# ddr32ss_EMIF_CTLCFG_0F308000h register map
Vendor: Texas Instruments
Registers are 32-bit, read-write, reset 0x0 unless marked. A register's access mark holds for its fields unless they carry their own. Offsets are as the file gives them; [hi:lo] are bit positions; lines under a group give offsets from that group; {n}, {i} and the like mark numbered series.

## emif_ctlcfg (part 13 of 13)
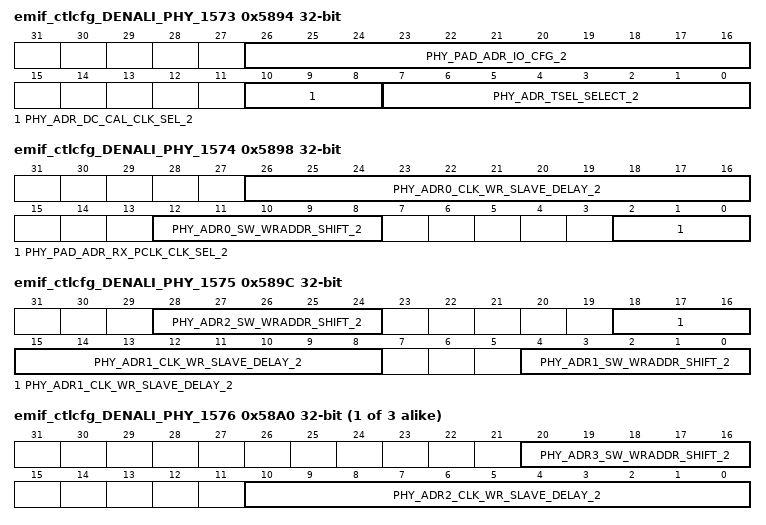
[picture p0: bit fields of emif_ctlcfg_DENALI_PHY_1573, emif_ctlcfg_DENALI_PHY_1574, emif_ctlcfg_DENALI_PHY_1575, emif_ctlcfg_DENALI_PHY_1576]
0x5894 emif_ctlcfg_DENALI_PHY_1573
  [26:16] PHY_PAD_ADR_IO_CFG_2 — Controls I/O pads for address pad for address slice 2. Bits [10:5] = Park value, bits [4] park override, bits [2:0] clk divider. Reset Source: ctl_amod_g_rst_n
  [10:8] PHY_ADR_DC_CAL_CLK_SEL_2 — DCC CAL clock for address slice 2. Reset Source: ctl_amod_g_rst_n
  [7:0] PHY_ADR_TSEL_SELECT_2 — Tsel select values for address slice 2. Reset Source: ctl_amod_g_rst_n
0x5898 emif_ctlcfg_DENALI_PHY_1574
  [26:16] PHY_ADR0_CLK_WR_SLAVE_DELAY_2 — CA bit 0 target delay setting for address slice 2. Reset Source: ctl_amod_g_rst_n
  [12:8] PHY_ADR0_SW_WRADDR_SHIFT_2 — Manual override of CA bit 0 of automatic half_cycle_shift/cycle_shift for address slice 2. Bit [0] enables override of half_cycle_shift. Bit [1] is the half_cycle_shift value. Bit [2] enables override of cycle shift. Bits [4:3] is the cycle_shift value. For bits [4:3], clear to 0x0 for no offset, program to 0x1 for -1 cycle, program to 0x2 for +1 cycle, or program to 0x3 for -2 cycles. Reset Source: ctl_amod_g_rst_n
  [2:0] PHY_PAD_ADR_RX_PCLK_CLK_SEL_2 — Reserved for address slice 2. Reset Source: ctl_amod_g_rst_n
0x589C emif_ctlcfg_DENALI_PHY_1575
  [28:24] PHY_ADR2_SW_WRADDR_SHIFT_2 — Manual override of CA bit 2 of automatic half_cycle_shift/cycle_shift for address slice 2. Bit [0] enables override of half_cycle_shift. Bit [1] is the half_cycle_shift value. Bit [2] enables override of cycle shift. Bits [4:3] is the cycle_shift value. For bits [4:3], clear to 0x0 for no offset, program to 0x1 for -1 cycle, program to 0x2 for +1 cycle, or program to 0x3 for -2 cycles. Reset Source: ctl_amod_g_rst_n
  [18:8] PHY_ADR1_CLK_WR_SLAVE_DELAY_2 — CA bit 1 target delay setting for address slice 2. Reset Source: ctl_amod_g_rst_n
  [4:0] PHY_ADR1_SW_WRADDR_SHIFT_2 — Manual override of CA bit 1 of automatic half_cycle_shift/cycle_shift for address slice 2. Bit [0] enables override of half_cycle_shift. Bit [1] is the half_cycle_shift value. Bit [2] enables override of cycle shift. Bits [4:3] is the cycle_shift value. For bits [4:3], clear to 0x0 for no offset, program to 0x1 for -1 cycle, program to 0x2 for +1 cycle, or program to 0x3 for -2 cycles. Reset Source: ctl_amod_g_rst_n
{0x4000+4i} emif_ctlcfg_DENALI_PHY_{i} (i=1576..1578)
  [20:16] PHY_ADR{i-1573}_SW_WRADDR_SHIFT_2 — Manual override of CA bit {i-1573} of automatic half_cycle_shift/cycle_shift for address slice 2. Bit [0] enables override of half_cycle_shift. Bit [1] is the half_cycle_shift value. Bit [2] enables override of cycle shift. Bits [4:3] is the cycle_shift value. For bits [4:3], clear to 0x0 for no offset, program to 0x1 for -1 cycle, program to 0x2 for +1 cycle, or program to 0x3 for -2 cycles. Reset Source: ctl_amod_g_rst_n
  [10:0] PHY_ADR{i-1574}_CLK_WR_SLAVE_DELAY_2 — CA bit {i-1574} target delay setting for address slice 2. Reset Source: ctl_amod_g_rst_n
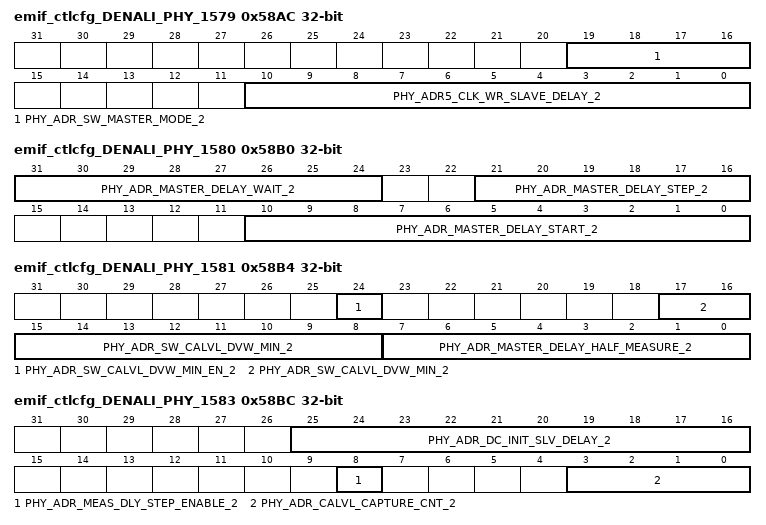
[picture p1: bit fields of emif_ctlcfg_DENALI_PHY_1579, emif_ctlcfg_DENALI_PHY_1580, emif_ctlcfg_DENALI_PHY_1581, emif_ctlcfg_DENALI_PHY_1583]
0x58AC emif_ctlcfg_DENALI_PHY_1579
  [19:16] PHY_ADR_SW_MASTER_MODE_2 — Master delay line override settings for address slice 2. Bit [0] enables software half clock mode. Bit [1] is the software half clock mode value. Bit [2] enables software bypass mode. Bit [3] is the software bypass mode value. Reset Source: ctl_amod_g_rst_n
  [10:0] PHY_ADR5_CLK_WR_SLAVE_DELAY_2 — CA bit 5 target delay setting for address slice 2. Reset Source: ctl_amod_g_rst_n
0x58B0 emif_ctlcfg_DENALI_PHY_1580
  [31:24] PHY_ADR_MASTER_DELAY_WAIT_2 — Wait cycles for master delay line locking algorithm for address slice 2. Bits [3:0] is the cycle wait count after a calibration clock setting change. Bits [7:4] is the cycle wait count after a master delay setting change. Reset Source: ctl_amod_g_rst_n
  [21:16] PHY_ADR_MASTER_DELAY_STEP_2 — Incremental step size for master delay line locking algorithm for address slice 2. Reset Source: ctl_amod_g_rst_n
  [10:0] PHY_ADR_MASTER_DELAY_START_2 — Start value for master delay line locking algorithm for address slice 2. Reset Source: ctl_amod_g_rst_n
0x58B4 emif_ctlcfg_DENALI_PHY_1581
  [24] PHY_ADR_SW_CALVL_DVW_MIN_EN_2 — Enables the software override data valid window size during CA training for address slice 2. Reset Source: ctl_amod_g_rst_n
  [17:8] PHY_ADR_SW_CALVL_DVW_MIN_2 — Sets the software override data valid window size during CA training for address slice 2. Reset Source: ctl_amod_g_rst_n
  [7:0] PHY_ADR_MASTER_DELAY_HALF_MEASURE_2 — Defines the number of delay line elements to be considered in determing whether to lock to a half clock cycle for the master in address slice 2 Reset Source: ctl_amod_g_rst_n
0x58B8 emif_ctlcfg_DENALI_PHY_1582
  [3:0] PHY_ADR_CALVL_DLY_STEP_2 — Sets the delay step size plus 1 during CA training for address slice 2. Reset Source: ctl_amod_g_rst_n
0x58BC emif_ctlcfg_DENALI_PHY_1583
  [25:16] PHY_ADR_DC_INIT_SLV_DELAY_2 — DCC initialization value of write ADDR target delay for address slice 2. Reset Source: ctl_amod_g_rst_n
  [8] PHY_ADR_MEAS_DLY_STEP_ENABLE_2 — Enables delay parameter setting using phy_adr_meas_dly_step_value for address slice 2. Reset Source: ctl_amod_g_rst_n
  [3:0] PHY_ADR_CALVL_CAPTURE_CNT_2 — Number of samples to take at each ADDR target delay setting during CA training for address slice 2. Reset Source: ctl_amod_g_rst_n
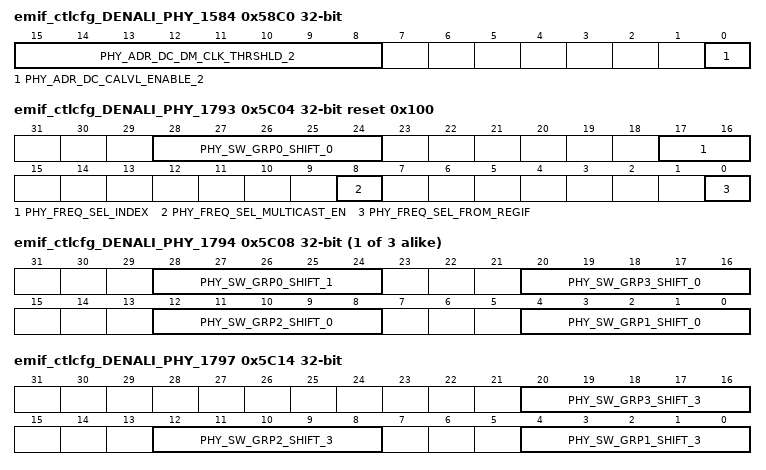
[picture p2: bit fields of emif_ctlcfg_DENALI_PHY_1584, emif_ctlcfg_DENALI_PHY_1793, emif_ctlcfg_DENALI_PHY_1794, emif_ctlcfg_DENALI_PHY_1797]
0x58C0 emif_ctlcfg_DENALI_PHY_1584
  [15:8] PHY_ADR_DC_DM_CLK_THRSHLD_2 — DCC clock measurement cell threshold offset for address slice 2. Reset Source: ctl_amod_g_rst_n
  [0] PHY_ADR_DC_CALVL_ENABLE_2 — DCC enable duty cycle adjust during CA leveling for address slice 2. Reset Source: ctl_amod_g_rst_n
0x5C00 emif_ctlcfg_DENALI_PHY_1792
  [1:0] PHY_FREQ_SEL — Specifies which copy of the frequency-dependent timing parameters will be used by the PHY. Reset Source: ctl_amod_g_rst_n
0x5C04 emif_ctlcfg_DENALI_PHY_1793 reset 0x100
  [28:24] PHY_SW_GRP0_SHIFT_0 — Address slice target delay setting for address slice 4. Reset Source: ctl_amod_g_rst_n
  [17:16] PHY_FREQ_SEL_INDEX — Selects which frequency set to update when PHY_FREQ_SEL_MULTICAST_EN is not set. Reset Source: ctl_amod_g_rst_n
  [8] PHY_FREQ_SEL_MULTICAST_EN — When set, a register write will update parameters for all frequency sets simultaneously. Set to 1 to enable. Reset Source: ctl_amod_g_rst_n
  [0] PHY_FREQ_SEL_FROM_REGIF — Indicates which source is used to select the frequency copy. When set to 1, the frequency select source is given by parameter PHY_FREQ_SEL from register I/F. When cleared to 0, the frequency select source is the PHY input signal dfi_frequency Reset Source: ctl_amod_g_rst_n
{0x4000+4i} emif_ctlcfg_DENALI_PHY_{i} (i=1794..1796)
  [28:24] PHY_SW_GRP0_SHIFT_{i-1793} — Address slice target delay setting for address slice 4. Reset Source: ctl_amod_g_rst_n
  [20:16] PHY_SW_GRP3_SHIFT_{i-1794} — Address slice target delay setting for address slice 4. Reset Source: ctl_amod_g_rst_n
  [12:8] PHY_SW_GRP2_SHIFT_{i-1794} — Address slice target delay setting for address slice 4. Reset Source: ctl_amod_g_rst_n
  [4:0] PHY_SW_GRP1_SHIFT_{i-1794} — Address slice target delay setting for address slice 4. Reset Source: ctl_amod_g_rst_n
0x5C14 emif_ctlcfg_DENALI_PHY_1797
  [20:16] PHY_SW_GRP3_SHIFT_3 — Address slice target delay setting for address slice 4. Reset Source: ctl_amod_g_rst_n
  [12:8] PHY_SW_GRP2_SHIFT_3 — Address slice target delay setting for address slice 4. Reset Source: ctl_amod_g_rst_n
  [4:0] PHY_SW_GRP1_SHIFT_3 — Address slice target delay setting for address slice 4. Reset Source: ctl_amod_g_rst_n
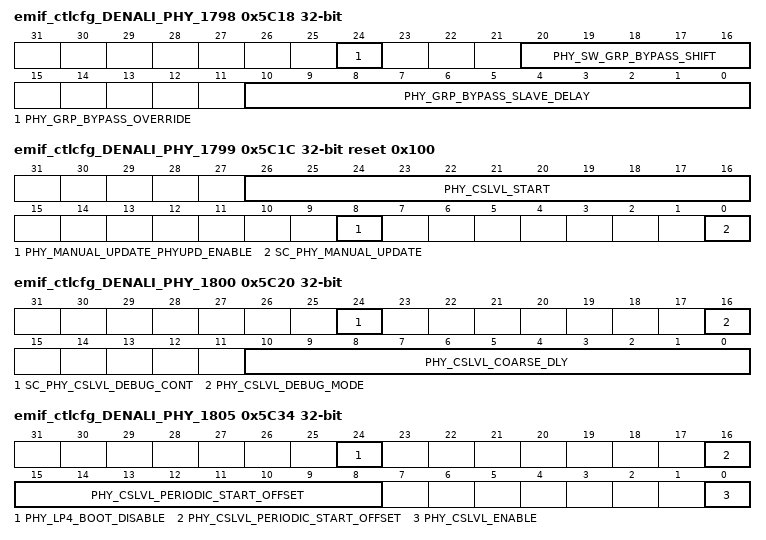
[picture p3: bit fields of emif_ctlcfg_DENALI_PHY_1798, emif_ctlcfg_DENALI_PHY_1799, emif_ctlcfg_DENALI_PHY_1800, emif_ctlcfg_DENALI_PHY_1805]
0x5C18 emif_ctlcfg_DENALI_PHY_1798
  [24] PHY_GRP_BYPASS_OVERRIDE — Address/control group slice bypass mode override setting. Reset Source: ctl_amod_g_rst_n
  [20:16] PHY_SW_GRP_BYPASS_SHIFT — Address/control group slice bypass mode shift settings. Reset Source: ctl_amod_g_rst_n
  [10:0] PHY_GRP_BYPASS_SLAVE_DELAY — Address/control group slice bypass mode target delay setting. Reset Source: ctl_amod_g_rst_n
0x5C1C emif_ctlcfg_DENALI_PHY_1799 access per field reset 0x100
  [26:16] PHY_CSLVL_START rw — Defines the CS training DDL start value. Reset Source: ctl_amod_g_rst_n
  [8] PHY_MANUAL_UPDATE_PHYUPD_ENABLE rw — Manual update selection of all target delay line settings. Set 1 to assert phyupd_req and wait phyupd_ack to update delay line, set 0 to update delay line directly. Reset Source: ctl_amod_g_rst_n
  [0] SC_PHY_MANUAL_UPDATE wo — Manual update of all target delay line settings. Set to 1 to trigger. WRITE-ONLY Reset Source: ctl_amod_g_rst_n
0x5C20 emif_ctlcfg_DENALI_PHY_1800 access per field
  [24] SC_PHY_CSLVL_DEBUG_CONT wo — Allows the CS training state machine to advance [when in debug mode]. Set to 1 to trigger. WRITE-ONLY Reset Source: ctl_amod_g_rst_n
  [16] PHY_CSLVL_DEBUG_MODE rw — Enables CS training debug mode. Set to 1 to enable. Reset Source: ctl_amod_g_rst_n
  [10:0] PHY_CSLVL_COARSE_DLY rw — Defines the CS training DDL coarse cycle delay value. Reset Source: ctl_amod_g_rst_n
0x5C24 emif_ctlcfg_DENALI_PHY_1801 wo
  [0] SC_PHY_CSLVL_ERROR_CLR — Clears the CS training state machine error status. Set to 1 to trigger. WRITE-ONLY Reset Source: ctl_amod_g_rst_n
0x5C28 emif_ctlcfg_DENALI_PHY_1802 ro reset 0x6800000
  [31:0] PHY_CSLVL_OBS0 — Observation register for CS training delay values. READ-ONLY Reset Source: ctl_amod_g_rst_n
0x5C2C emif_ctlcfg_DENALI_PHY_1803 ro
  [31:0] PHY_CSLVL_OBS1 — Observation register for CS training algorithm status. READ-ONLY Reset Source: ctl_amod_g_rst_n
0x5C30 emif_ctlcfg_DENALI_PHY_1804 ro
  [31:0] PHY_CSLVL_OBS2 — Observation register for periodic CS training delay values. READ-ONLY Reset Source: ctl_amod_g_rst_n
0x5C34 emif_ctlcfg_DENALI_PHY_1805
  [24] PHY_LP4_BOOT_DISABLE — Controls the handling of the DFI frequency. When set to 1, DFI frequency 0 is considered the first operational frequency. When cleared to 0, DFI frequency 0 is the boot frequency and other DFI frequency values are operational frequencies. Must be cleared to 0 for LPDDR3 devices operating in an LPDDR4 capable configuration. Reset Source: ctl_amod_g_rst_n
  [16:8] PHY_CSLVL_PERIODIC_START_OFFSET — Defines the relative offset from previous LE and TE to start periodic CSLVL with. Reset Source: ctl_amod_g_rst_n
  [0] PHY_CSLVL_ENABLE — CS training enable. Set to 1 to enable CS training during CA training. Reset Source: ctl_amod_g_rst_n
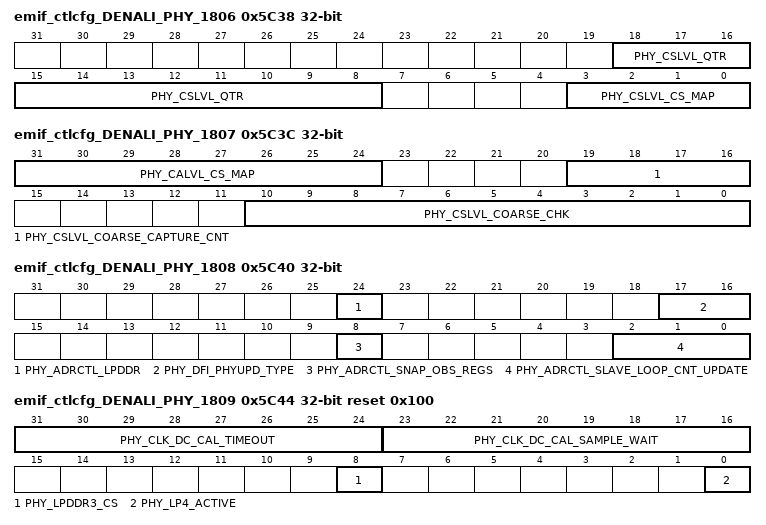
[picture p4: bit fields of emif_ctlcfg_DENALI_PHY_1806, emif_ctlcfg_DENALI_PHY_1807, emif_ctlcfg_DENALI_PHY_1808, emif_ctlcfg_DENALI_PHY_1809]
0x5C38 emif_ctlcfg_DENALI_PHY_1806
  [18:8] PHY_CSLVL_QTR — Defines the CS training DDL 1/4 cycle delay value. Reset Source: ctl_amod_g_rst_n
  [3:0] PHY_CSLVL_CS_MAP — CS training map. Set each CS bit to 1 to allow that CS to participate in CS training results. NOT CURRENTLY USED. Reset Source: ctl_amod_g_rst_n
0x5C3C emif_ctlcfg_DENALI_PHY_1807
  [31:24] PHY_CALVL_CS_MAP — Defines the slice numbers associated with each CS during CA training. Reset Source: ctl_amod_g_rst_n
  [19:16] PHY_CSLVL_COARSE_CAPTURE_CNT — Defines the number of samples to take at each GRP target delay setting during CS training coarse CA training. Reset Source: ctl_amod_g_rst_n
  [10:0] PHY_CSLVL_COARSE_CHK — Defines the CS training coarse CA training DDL 1/16th cycle delay value. Reset Source: ctl_amod_g_rst_n
0x5C40 emif_ctlcfg_DENALI_PHY_1808 access per field
  [24] PHY_ADRCTL_LPDDR rw — Adds a cycle of delay for the address/control slices to match the address slice. Reset Source: ctl_amod_g_rst_n
  [17:16] PHY_DFI_PHYUPD_TYPE rw — Defines the value of the dfi_phyupd_type output signal to MC. Reset Source: ctl_amod_g_rst_n
  [8] PHY_ADRCTL_SNAP_OBS_REGS wo — Initiates a snapshot of the internal observation registers for the address/control block. Set to 1 to trigger. WRITE-ONLY Reset Source: ctl_amod_g_rst_n
  [2:0] PHY_ADRCTL_SLAVE_LOOP_CNT_UPDATE rw — Reserved for the address/control master. Reset Source: ctl_amod_g_rst_n
0x5C44 emif_ctlcfg_DENALI_PHY_1809 reset 0x100
  [31:24] PHY_CLK_DC_CAL_TIMEOUT — Duty cycle correction maximum iteration count. Reset Source: ctl_amod_g_rst_n
  [23:16] PHY_CLK_DC_CAL_SAMPLE_WAIT — Number of cal clock cycles to wait for a sample to be taken. Reset Source: ctl_amod_g_rst_n
  [8] PHY_LPDDR3_CS — Alters reset state polarity for LPDDR chip selects. Reset Source: ctl_amod_g_rst_n
  [0] PHY_LP4_ACTIVE — Indicates an LPDDR4 device is connected to the PHY. Reset Source: ctl_amod_g_rst_n
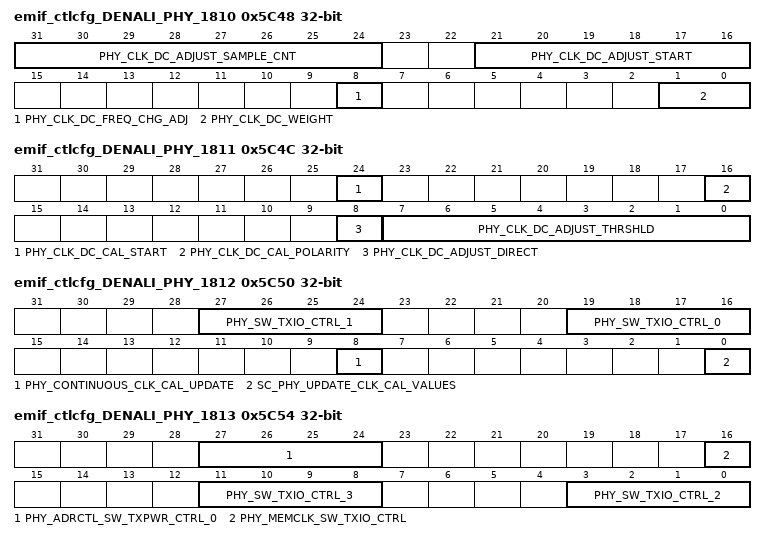
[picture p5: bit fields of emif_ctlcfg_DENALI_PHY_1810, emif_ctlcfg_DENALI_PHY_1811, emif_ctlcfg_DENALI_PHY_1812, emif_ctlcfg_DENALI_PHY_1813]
0x5C48 emif_ctlcfg_DENALI_PHY_1810
  [31:24] PHY_CLK_DC_ADJUST_SAMPLE_CNT — Duty cycle correction algorithm sample count per adjustment setting. Reset Source: ctl_amod_g_rst_n
  [21:16] PHY_CLK_DC_ADJUST_START — Duty cycle correction algorithm adjustment starting value. Reset Source: ctl_amod_g_rst_n
  [8] PHY_CLK_DC_FREQ_CHG_ADJ — Duty cycle correction during frequency change control. Reset Source: ctl_amod_g_rst_n
  [1:0] PHY_CLK_DC_WEIGHT — Duty cycle correction weighting factor base value. Reset Source: ctl_amod_g_rst_n
0x5C4C emif_ctlcfg_DENALI_PHY_1811
  [24] PHY_CLK_DC_CAL_START — Duty cycle correction calibration manual start. Reset Source: ctl_amod_g_rst_n
  [16] PHY_CLK_DC_CAL_POLARITY — Duty cycle correction algorithm measurement polarity. Reset Source: ctl_amod_g_rst_n
  [8] PHY_CLK_DC_ADJUST_DIRECT — Duty cycle correction algorithm adjustment direction. Reset Source: ctl_amod_g_rst_n
  [7:0] PHY_CLK_DC_ADJUST_THRSHLD — Duty cycle correction algorithm threshold delta comparison. Reset Source: ctl_amod_g_rst_n
0x5C50 emif_ctlcfg_DENALI_PHY_1812 access per field
  [27:24] PHY_SW_TXIO_CTRL_1 rw — This register is used to control if command pad [CS/RAS...] should be shutoff for TX mode. Reset Source: ctl_amod_g_rst_n
  [19:16] PHY_SW_TXIO_CTRL_0 rw — This register is used to control if command pad [CS/RAS...] should be shutoff for TX mode. Reset Source: ctl_amod_g_rst_n
  [8] PHY_CONTINUOUS_CLK_CAL_UPDATE rw — Continuous update of all latest PVTP,PVTN and PVTR values to the CLK IO pads. Set to 1 to keep this enabled. Reset Source: ctl_amod_g_rst_n
  [0] SC_PHY_UPDATE_CLK_CAL_VALUES wo — Manual update of all latest PVTP,PVTN and PVTR values to the CLK IO pads. Set to 1 to trigger. WRITE-ONLY Reset Source: ctl_amod_g_rst_n
0x5C54 emif_ctlcfg_DENALI_PHY_1813
  [27:24] PHY_ADRCTL_SW_TXPWR_CTRL_0 — This register is used to control if address/command pad [address/CS/RAS...] should be shutoff for TX mode in deep sleep mode. Reset Source: ctl_amod_g_rst_n
  [16] PHY_MEMCLK_SW_TXIO_CTRL — This register is used to control if clk pads should be shutoff for TX mode. Reset Source: ctl_amod_g_rst_n
  [11:8] PHY_SW_TXIO_CTRL_3 — This register is used to control if command pad [CS/RAS...] should be shutoff for TX mode. Reset Source: ctl_amod_g_rst_n
  [3:0] PHY_SW_TXIO_CTRL_2 — This register is used to control if command pad [CS/RAS...] should be shutoff for TX mode. Reset Source: ctl_amod_g_rst_n
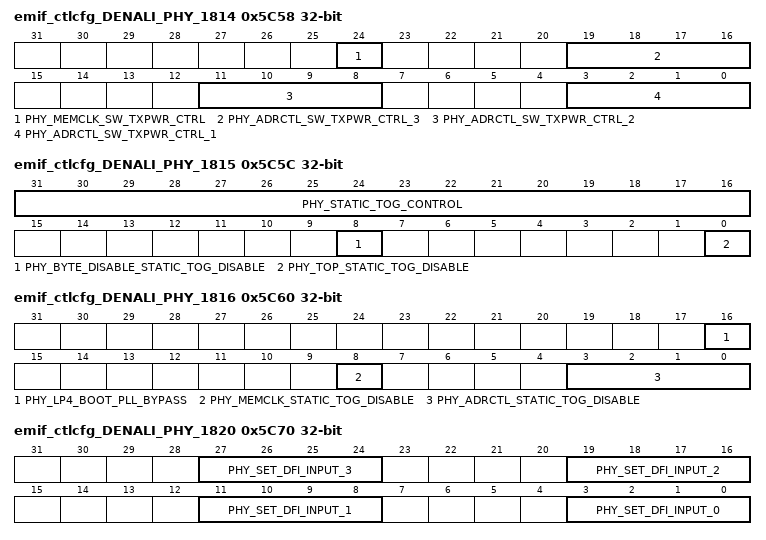
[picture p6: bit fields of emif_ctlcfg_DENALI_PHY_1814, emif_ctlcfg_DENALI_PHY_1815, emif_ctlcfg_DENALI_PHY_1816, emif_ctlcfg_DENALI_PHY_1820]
0x5C58 emif_ctlcfg_DENALI_PHY_1814
  [24] PHY_MEMCLK_SW_TXPWR_CTRL — This register is used to control if clk pads should be shutoff for TX mode in deep sleep mode. Reset Source: ctl_amod_g_rst_n
  [19:16] PHY_ADRCTL_SW_TXPWR_CTRL_3 — This register is used to control if address/command pad [address/CS/RAS...] should be shutoff for TX mode in deep sleep mode. Reset Source: ctl_amod_g_rst_n
  [11:8] PHY_ADRCTL_SW_TXPWR_CTRL_2 — This register is used to control if address/command pad [address/CS/RAS...] should be shutoff for TX mode in deep sleep mode. Reset Source: ctl_amod_g_rst_n
  [3:0] PHY_ADRCTL_SW_TXPWR_CTRL_1 — This register is used to control if address/command pad [address/CS/RAS...] should be shutoff for TX mode in deep sleep mode. Reset Source: ctl_amod_g_rst_n
0x5C5C emif_ctlcfg_DENALI_PHY_1815
  [31:16] PHY_STATIC_TOG_CONTROL — Clock divider to create toggle signal. Use long counter as the base. Reset Source: ctl_amod_g_rst_n
  [8] PHY_BYTE_DISABLE_STATIC_TOG_DISABLE — Control to disable the toggle signal for data slice during static activity when dfi_data_byte_disable is asserted. Reset Source: ctl_amod_g_rst_n
  [0] PHY_TOP_STATIC_TOG_DISABLE — Disables the generation of the toggle for static clock based paths in the PHY to prevent assymetric aging. Reset Source: ctl_amod_g_rst_n
0x5C60 emif_ctlcfg_DENALI_PHY_1816
  [16] PHY_LP4_BOOT_PLL_BYPASS — PHY clock PLL bypass select. Reset Source: ctl_amod_g_rst_n
  [8] PHY_MEMCLK_STATIC_TOG_DISABLE — Control to disable toggle during static activity. bit0: clock disable. Reset Source: ctl_amod_g_rst_n
  [3:0] PHY_ADRCTL_STATIC_TOG_DISABLE — Control to disable toggle during static activity. bit0: Write path delay line disable; bit1: clock disable; bit2: adrctl master delay line disable [if exists]; bit3: adrctl misc core clk disable.[if exists] Reset Source: ctl_amod_g_rst_n
0x5C64 emif_ctlcfg_DENALI_PHY_1817 ro reset 0x10082650
  [31:0] PHY_CLK_SWITCH_OBS — Observation register for Clock switch state machine READ-ONLY Reset Source: ctl_amod_g_rst_n
0x5C68 emif_ctlcfg_DENALI_PHY_1818
  [15:0] PHY_PLL_WAIT — PHY clock PLL wait time after locking. Reset Source: ctl_amod_g_rst_n
0x5C6C emif_ctlcfg_DENALI_PHY_1819
  [0] PHY_SW_PLL_BYPASS — PHY clock PLL bypass select. Reset Source: ctl_amod_g_rst_n
0x5C70 emif_ctlcfg_DENALI_PHY_1820
  [8n+3:8n] PHY_SET_DFI_INPUT_{n} (n=0..3) — Used to indicate the default value of the adrctl slice bits. Reset Source: ctl_amod_g_rst_n
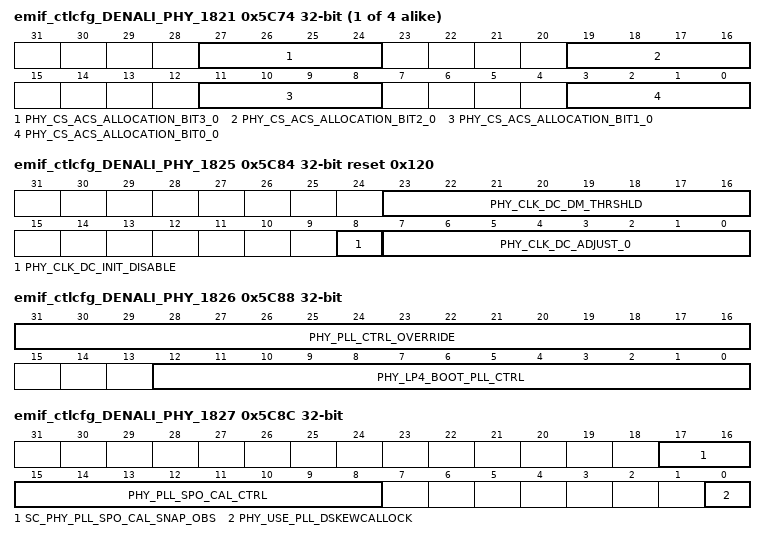
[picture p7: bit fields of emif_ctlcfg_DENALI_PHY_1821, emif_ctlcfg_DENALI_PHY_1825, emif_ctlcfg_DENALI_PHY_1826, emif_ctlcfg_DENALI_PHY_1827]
{0x4000+4i} emif_ctlcfg_DENALI_PHY_{i} (i=1821..1824)
  [27:24] PHY_CS_ACS_ALLOCATION_BIT3_{i-1821} — The map for which chip select is associated with each bit in the adrctl slice {i-1821}. Bit [n], 1 means cs[n]'s signal[CS/CKE/ODT/RST] is allocated on ACS_{i-1821} bit3, 0 means cs[n]'s signal[CS/CKE/ODT/RST] is not tranfser on ACS_{i-1821}, if the accroding cs[n]'s training is not enabled, need to set the value to all 1s. Reset Source: ctl_amod_g_rst_n
  [19:16] PHY_CS_ACS_ALLOCATION_BIT2_{i-1821} — The map for which chip select is associated with each bit in the adrctl slice {i-1821}. Bit [n], 1 means cs[n]'s signal[CS/CKE/ODT/RST] is allocated on ACS_{i-1821} bit2 , 0 means cs[n]'s signal[CS/CKE/ODT/RST] is not tranfser on ACS_{i-1821}, if the accroding cs[n]'s training is not enabled, need to set the value to all 1s. Reset Source: ctl_amod_g_rst_n
  [11:8] PHY_CS_ACS_ALLOCATION_BIT1_{i-1821} — The map for which chip select is associated with each bit in the adrctl slice {i-1821}. Bit [n], 1 means cs[n]'s signal[CS/CKE/ODT/RST] is allocated on ACS_{i-1821} bit1, 0 means cs[n]'s signal[CS/CKE/ODT/RST] is not tranfser on ACS_{i-1821}, if the accroding cs[n]'s training is not enabled, need to set the value to all 1s. Reset Source: ctl_amod_g_rst_n
  [3:0] PHY_CS_ACS_ALLOCATION_BIT0_{i-1821} — The map for which chip select is associated with each bit in the adrctl slice {i-1821}. Bit [n], 1 means cs[n]'s signal[CS/CKE/ODT/RST] is allocated on ACS_{i-1821} bit0, 0 means cs[n]'s signal[CS/CKE/ODT/RST] is not tranfser on ACS_{i-1821}, if the accroding cs[n]'s training is not enabled, need to set the value to all 1s. Reset Source: ctl_amod_g_rst_n
0x5C84 emif_ctlcfg_DENALI_PHY_1825 reset 0x120
  [23:16] PHY_CLK_DC_DM_THRSHLD — Data measurement cell threshold offset. Reset Source: ctl_amod_g_rst_n
  [8] PHY_CLK_DC_INIT_DISABLE — Disable duty cycle adjust at initialization. Reset Source: ctl_amod_g_rst_n
  [7:0] PHY_CLK_DC_ADJUST_0 — Adjust value of Duty Cycle Adjuster for clock slice 0. Reset Source: ctl_amod_g_rst_n
0x5C88 emif_ctlcfg_DENALI_PHY_1826
  [31:16] PHY_PLL_CTRL_OVERRIDE — Individual PHY clock PLL control overrides. Reset Source: ctl_amod_g_rst_n
  [12:0] PHY_LP4_BOOT_PLL_CTRL — PHY deskew PLL controls for LPDDR4 boot frequency. Reset Source: ctl_amod_g_rst_n
0x5C8C emif_ctlcfg_DENALI_PHY_1827 access per field
  [17:16] SC_PHY_PLL_SPO_CAL_SNAP_OBS wo — Register command to take a snapshot of PLL output. WRITE-ONLY Reset Source: ctl_amod_g_rst_n
  [15:8] PHY_PLL_SPO_CAL_CTRL rw — PLL SPO Cal controls. Reset Source: ctl_amod_g_rst_n
  [0] PHY_USE_PLL_DSKEWCALLOCK rw — Use DSKEWCALLOCK or not. Reset Source: ctl_amod_g_rst_n
0x5C90 emif_ctlcfg_DENALI_PHY_1828 ro
  [15:0] PHY_PLL_OBS_0 — PHY TOP level clock PLL_0 observe values. READ-ONLY Reset Source: ctl_amod_g_rst_n
0x5C94 emif_ctlcfg_DENALI_PHY_1829 ro
  [16:0] PHY_PLL_SPO_CAL_OBS_0 — PHY TOP level PLL_0 SPO Cal observe values. READ-ONLY Reset Source: ctl_amod_g_rst_n
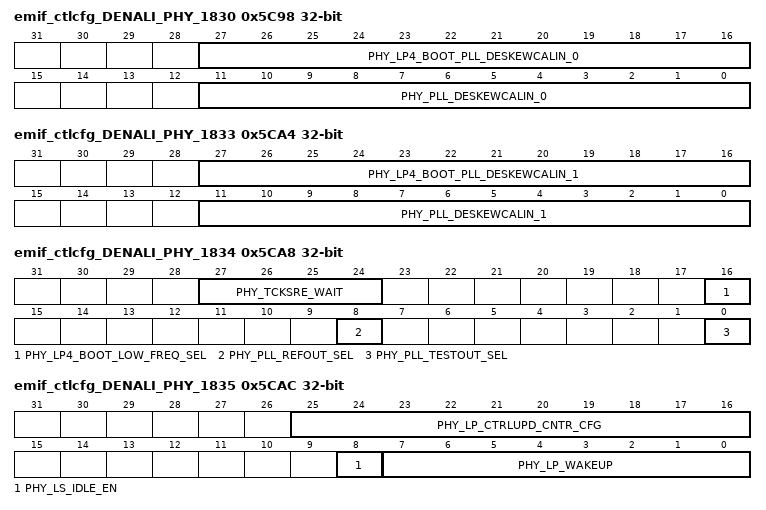
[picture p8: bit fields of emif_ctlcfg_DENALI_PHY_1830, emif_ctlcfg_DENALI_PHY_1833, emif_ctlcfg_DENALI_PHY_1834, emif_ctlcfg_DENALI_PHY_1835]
0x5C98 emif_ctlcfg_DENALI_PHY_1830
  [27:16] PHY_LP4_BOOT_PLL_DESKEWCALIN_0 — PHY TOP level PLL_0 lpddr4 boot deskewcal in values. Reset Source: ctl_amod_g_rst_n
  [11:0] PHY_PLL_DESKEWCALIN_0 — PHY TOP level PLL_0 deskewcal in values. Reset Source: ctl_amod_g_rst_n
0x5C9C emif_ctlcfg_DENALI_PHY_1831 ro
  [15:0] PHY_PLL_OBS_1 — PHY TOP level clock PLL_1 observe values. READ-ONLY Reset Source: ctl_amod_g_rst_n
0x5CA0 emif_ctlcfg_DENALI_PHY_1832 ro
  [16:0] PHY_PLL_SPO_CAL_OBS_1 — PHY TOP level PLL_1 SPO Cal observe values. READ-ONLY Reset Source: ctl_amod_g_rst_n
0x5CA4 emif_ctlcfg_DENALI_PHY_1833
  [27:16] PHY_LP4_BOOT_PLL_DESKEWCALIN_1 — PHY TOP level PLL_1 lpddr4 boot deskewcal in values. Reset Source: ctl_amod_g_rst_n
  [11:0] PHY_PLL_DESKEWCALIN_1 — PHY TOP level PLL_1 deskewcal in values. Reset Source: ctl_amod_g_rst_n
0x5CA8 emif_ctlcfg_DENALI_PHY_1834
  [27:24] PHY_TCKSRE_WAIT — Specifies the number of cycles the PHY should wait before turning off the PLL for a deep sleep or DFS event. Reset Source: ctl_amod_g_rst_n
  [16] PHY_LP4_BOOT_LOW_FREQ_SEL — Control the PLL domain enter/exit from the negative clock edge for LPDDR4 boot frequency. Reset Source: ctl_amod_g_rst_n
  [8] PHY_PLL_REFOUT_SEL — PHY PLL refout select. Reset Source: ctl_amod_g_rst_n
  [0] PHY_PLL_TESTOUT_SEL — PHY PLL testout select. Reset Source: ctl_amod_g_rst_n
0x5CAC emif_ctlcfg_DENALI_PHY_1835
  [25:16] PHY_LP_CTRLUPD_CNTR_CFG — Specifies the number of cycles the PHY takes from light sleep req deassert to ack deassert in low power mode. Reset Source: ctl_amod_g_rst_n
  [8] PHY_LS_IDLE_EN — Indicates the Reduced Idle Power State is enabled in low power mode. Reset Source: ctl_amod_g_rst_n
  [7:0] PHY_LP_WAKEUP — Specifies the number of cycles the PHY takes to wakeup in low power mode. Reset Source: ctl_amod_g_rst_n
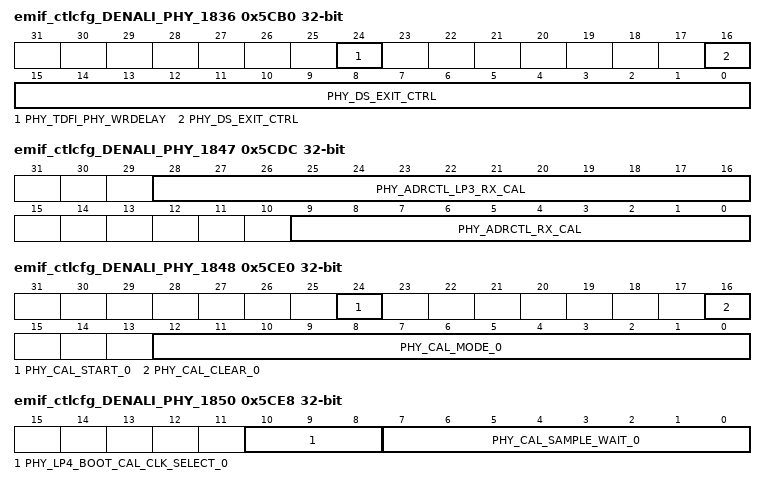
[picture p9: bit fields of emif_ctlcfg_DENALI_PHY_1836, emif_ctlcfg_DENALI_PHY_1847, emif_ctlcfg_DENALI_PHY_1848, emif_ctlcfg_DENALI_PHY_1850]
0x5CB0 emif_ctlcfg_DENALI_PHY_1836
  [24] PHY_TDFI_PHY_WRDELAY — DFI timing parameter TDFI_PHY_WRDELAY. Reset Source: ctl_amod_g_rst_n
  [16:0] PHY_DS_EXIT_CTRL — Controls to reduce the deep sleep exit latency, when bit 16 is 1 deep sleep exit ack won't wait master delay line lock. Reset Source: ctl_amod_g_rst_n
0x5CB4 emif_ctlcfg_DENALI_PHY_1837 reset 0x4410
  [17:0] PHY_PAD_FDBK_TERM — Controls term settings for gate feedback pads. Reset Source: ctl_amod_g_rst_n
0x5CB8 emif_ctlcfg_DENALI_PHY_1838 reset 0x4410
  [16:0] PHY_PAD_DATA_TERM — Controls term settings for data pads. Reset Source: ctl_amod_g_rst_n
0x5CBC emif_ctlcfg_DENALI_PHY_1839 reset 0x4410
  [16:0] PHY_PAD_DQS_TERM — Controls term settings for dqs pads. Reset Source: ctl_amod_g_rst_n
0x5CC0 emif_ctlcfg_DENALI_PHY_1840 reset 0x4410
  [17:0] PHY_PAD_ADDR_TERM — Controls term settings for the address/control pads. Reset Source: ctl_amod_g_rst_n
0x5CC4 emif_ctlcfg_DENALI_PHY_1841 reset 0x4410
  [17:0] PHY_PAD_CLK_TERM — Controls term settings for clock pads. Reset Source: ctl_amod_g_rst_n
0x5CC8 emif_ctlcfg_DENALI_PHY_1842 reset 0x4410
  [17:0] PHY_PAD_ERR_TERM — Controls term settings for error pads. Reset Source: ctl_amod_g_rst_n
0x5CCC emif_ctlcfg_DENALI_PHY_1843 reset 0x4410
  [17:0] PHY_PAD_CKE_TERM — Controls term settings for cke pads. Reset Source: ctl_amod_g_rst_n
0x5CD0 emif_ctlcfg_DENALI_PHY_1844 reset 0x4410
  [17:0] PHY_PAD_RST_TERM — Controls term settings for reset_n pads. Reset Source: ctl_amod_g_rst_n
0x5CD4 emif_ctlcfg_DENALI_PHY_1845 reset 0x4410
  [17:0] PHY_PAD_CS_TERM — Controls term settings for cs pads. Reset Source: ctl_amod_g_rst_n
0x5CD8 emif_ctlcfg_DENALI_PHY_1846 reset 0x4410
  [17:0] PHY_PAD_ODT_TERM — Controls term settings for odt pads. Reset Source: ctl_amod_g_rst_n
0x5CDC emif_ctlcfg_DENALI_PHY_1847
  [28:16] PHY_ADRCTL_LP3_RX_CAL — PHY CKE/RESET_N RX calibration controls. Reset Source: ctl_amod_g_rst_n
  [9:0] PHY_ADRCTL_RX_CAL — PHY address/control RX calibration controls. Reset Source: ctl_amod_g_rst_n
0x5CE0 emif_ctlcfg_DENALI_PHY_1848 access per field
  [24] PHY_CAL_START_0 wo — Manual start for the pad calibration state machine for block 0. Set to 1 to trigger. WRITE-ONLY Reset Source: ctl_amod_g_rst_n
  [16] PHY_CAL_CLEAR_0 wo — Clear the pad calibration state machine and results for block 0. Set to 1 to trigger. WRITE-ONLY Reset Source: ctl_amod_g_rst_n
  [12:0] PHY_CAL_MODE_0 rw — Pad calibration mode bits for block 0. Bit [0] disables pad calibration upon initialization. Bit [1] enables automatic interval based calibration. Bits [3:2] set the base interval for the interval counter. Bits [7:4] are direct connections to pad control signals. Reset Source: ctl_amod_g_rst_n
0x5CE4 emif_ctlcfg_DENALI_PHY_1849
  [31:0] PHY_CAL_INTERVAL_COUNT_0 — Pad calibration interval counter compare value for block 0. Reset Source: ctl_amod_g_rst_n
0x5CE8 emif_ctlcfg_DENALI_PHY_1850
  [10:8] PHY_LP4_BOOT_CAL_CLK_SELECT_0 — Pad calibration pad clock frequency select setting for LPDDR4 boot frequency for block 0. Reset Source: ctl_amod_g_rst_n
  [7:0] PHY_CAL_SAMPLE_WAIT_0 — Pad calibration state machine wait count in pad clock cycles for block 0. Reset Source: ctl_amod_g_rst_n
0x5CEC emif_ctlcfg_DENALI_PHY_1851 ro
  [23:0] PHY_CAL_RESULT_OBS_0 — Pad calibration results observation values for block 0. READ-ONLY Reset Source: ctl_amod_g_rst_n
0x5CF0 emif_ctlcfg_DENALI_PHY_1852 ro
  [23:0] PHY_CAL_RESULT2_OBS_0 — Pad calibration results [CKE/RESET_N] observation values for block 0. READ-ONLY Reset Source: ctl_amod_g_rst_n
0x5CF4 emif_ctlcfg_DENALI_PHY_1853 ro
  [23:0] PHY_CAL_RESULT4_OBS_0 — Pad calibration pass1 shadow results observation values for block 0. READ-ONLY Reset Source: ctl_amod_g_rst_n
0x5CF8 emif_ctlcfg_DENALI_PHY_1854 ro
  [23:0] PHY_CAL_RESULT5_OBS_0 — Pad calibration pass2 shadow results observation values for block 0. READ-ONLY Reset Source: ctl_amod_g_rst_n
0x5CFC emif_ctlcfg_DENALI_PHY_1855 ro
  [23:0] PHY_CAL_RESULT6_OBS_0 — Pad calibration internal results observation delta values for block 0. READ-ONLY Reset Source: ctl_amod_g_rst_n
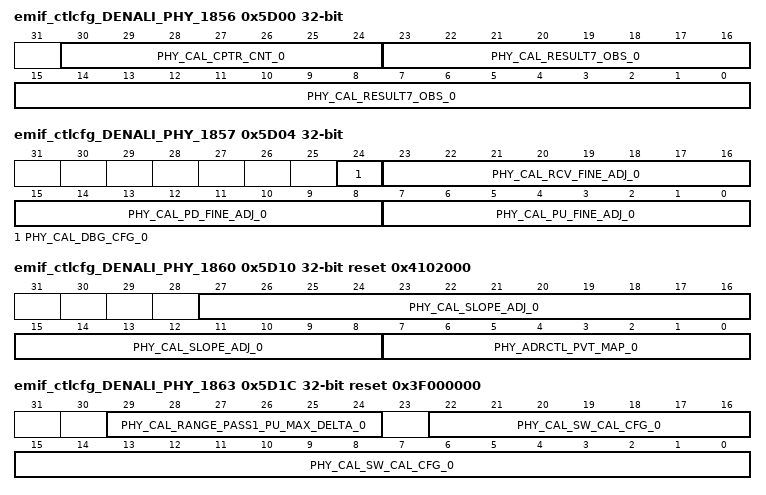
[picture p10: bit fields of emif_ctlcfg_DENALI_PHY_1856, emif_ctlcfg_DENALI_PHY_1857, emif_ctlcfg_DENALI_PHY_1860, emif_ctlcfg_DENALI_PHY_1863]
0x5D00 emif_ctlcfg_DENALI_PHY_1856 access per field
  [30:24] PHY_CAL_CPTR_CNT_0 rw — defines sample capture number in pad calibration process Reset Source: ctl_amod_g_rst_n
  [23:0] PHY_CAL_RESULT7_OBS_0 ro — Pad calibration internal results observation delta values for block 0. READ-ONLY Reset Source: ctl_amod_g_rst_n
0x5D04 emif_ctlcfg_DENALI_PHY_1857
  [24] PHY_CAL_DBG_CFG_0 — defines debug configuration in pad calibration process Reset Source: ctl_amod_g_rst_n
  [23:16] PHY_CAL_RCV_FINE_ADJ_0 — defines adjustment for RCV code in pad calibration process Reset Source: ctl_amod_g_rst_n
  [15:8] PHY_CAL_PD_FINE_ADJ_0 — defines adjustment for PD code in pad calibration process Reset Source: ctl_amod_g_rst_n
  [7:0] PHY_CAL_PU_FINE_ADJ_0 — defines adjustment for PU code in pad calibration process Reset Source: ctl_amod_g_rst_n
0x5D08 emif_ctlcfg_DENALI_PHY_1858 wo
  [0] SC_PHY_PAD_DBG_CONT_0 — Allows the pad calibration state machine to advance [when in debug mode] for slice 0. Set to 1 to trigger. WRITE-ONLY Reset Source: ctl_amod_g_rst_n
0x5D0C emif_ctlcfg_DENALI_PHY_1859 ro
  [31:0] PHY_CAL_RESULT3_OBS_0 — Pad calibration results first/last0/1 observation values for block 0. READ-ONLY Reset Source: ctl_amod_g_rst_n
0x5D10 emif_ctlcfg_DENALI_PHY_1860 reset 0x4102000
  [27:8] PHY_CAL_SLOPE_ADJ_0 — defines slope configure in pad calibration process Reset Source: ctl_amod_g_rst_n
  [7:0] PHY_ADRCTL_PVT_MAP_0 — defines slope configure in pad calibration process Reset Source: ctl_amod_g_rst_n
0x5D14 emif_ctlcfg_DENALI_PHY_1861 reset 0x41020
  [19:0] PHY_CAL_SLOPE_ADJ_PASS2_0 — defines slope configure for pass2 in pad calibration process Reset Source: ctl_amod_g_rst_n
0x5D18 emif_ctlcfg_DENALI_PHY_1862 reset 0xC98C98
  [24:0] PHY_CAL_TWO_PASS_CFG_0 — defines cal_en configure in pad calibration process Reset Source: ctl_amod_g_rst_n
0x5D1C emif_ctlcfg_DENALI_PHY_1863 reset 0x3F000000
  [29:24] PHY_CAL_RANGE_PASS1_PU_MAX_DELTA_0 — Pad calibration pass1 pu results won't update if out of max delta range . Reset Source: ctl_amod_g_rst_n
  [22:0] PHY_CAL_SW_CAL_CFG_0 — defines firmware based pad calibration process Reset Source: ctl_amod_g_rst_n
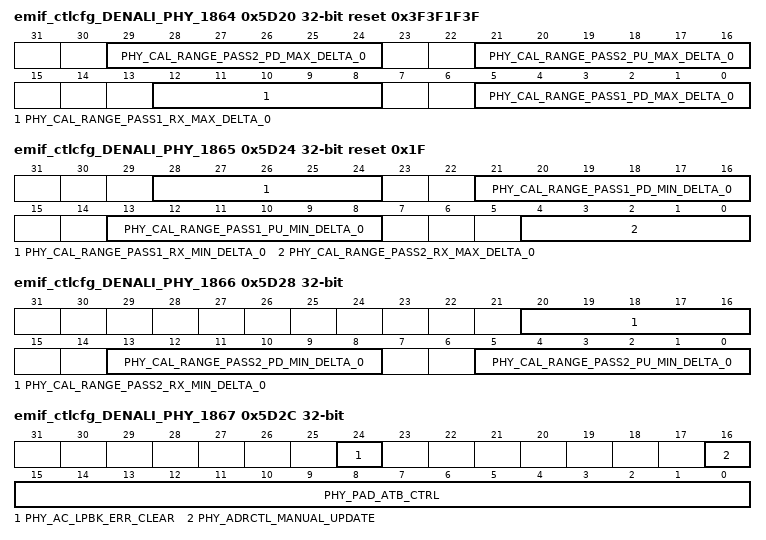
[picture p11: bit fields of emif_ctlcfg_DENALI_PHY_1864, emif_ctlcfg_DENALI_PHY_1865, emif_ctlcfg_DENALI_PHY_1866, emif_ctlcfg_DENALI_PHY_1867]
0x5D20 emif_ctlcfg_DENALI_PHY_1864 reset 0x3F3F1F3F
  [29:24] PHY_CAL_RANGE_PASS2_PD_MAX_DELTA_0 — Pad calibration pass2 pd results won't update if out of max delta range . Reset Source: ctl_amod_g_rst_n
  [21:16] PHY_CAL_RANGE_PASS2_PU_MAX_DELTA_0 — Pad calibration pass2 pu results won't update if out of max delta range . Reset Source: ctl_amod_g_rst_n
  [12:8] PHY_CAL_RANGE_PASS1_RX_MAX_DELTA_0 — Pad calibration pass1 rx results won't update if out of max delta range . Reset Source: ctl_amod_g_rst_n
  [5:0] PHY_CAL_RANGE_PASS1_PD_MAX_DELTA_0 — Pad calibration pass1 pd results won't update if out of max delta range . Reset Source: ctl_amod_g_rst_n
0x5D24 emif_ctlcfg_DENALI_PHY_1865 reset 0x1F
  [28:24] PHY_CAL_RANGE_PASS1_RX_MIN_DELTA_0 — Pad calibration pass1 rx results won't update if out of min delta range . Reset Source: ctl_amod_g_rst_n
  [21:16] PHY_CAL_RANGE_PASS1_PD_MIN_DELTA_0 — Pad calibration pass1 pd results won't update if out of min delta range . Reset Source: ctl_amod_g_rst_n
  [13:8] PHY_CAL_RANGE_PASS1_PU_MIN_DELTA_0 — Pad calibration pass1 pu results won't update if out of min delta range . Reset Source: ctl_amod_g_rst_n
  [4:0] PHY_CAL_RANGE_PASS2_RX_MAX_DELTA_0 — Pad calibration pass2 rx results won't update if out of max delta range . Reset Source: ctl_amod_g_rst_n
0x5D28 emif_ctlcfg_DENALI_PHY_1866
  [20:16] PHY_CAL_RANGE_PASS2_RX_MIN_DELTA_0 — Pad calibration pass2 rx results won't update if out of min delta range . Reset Source: ctl_amod_g_rst_n
  [13:8] PHY_CAL_RANGE_PASS2_PD_MIN_DELTA_0 — Pad calibration pass2 pd results won't update if out of min delta range . Reset Source: ctl_amod_g_rst_n
  [5:0] PHY_CAL_RANGE_PASS2_PU_MIN_DELTA_0 — Pad calibration pass2 pu results won't update if out of min delta range . Reset Source: ctl_amod_g_rst_n
0x5D2C emif_ctlcfg_DENALI_PHY_1867 access per field
  [24] PHY_AC_LPBK_ERR_CLEAR wo — Address/control loopback error clear. Set to 1 to clear error. WRITE-ONLY Reset Source: ctl_amod_g_rst_n
  [16] PHY_ADRCTL_MANUAL_UPDATE wo — Address/control manual update of target delay lines. Set to 1 to update. WRITE-ONLY Reset Source: ctl_amod_g_rst_n
  [15:0] PHY_PAD_ATB_CTRL rw — Pad ATB control settings. Bit [0] is the enable signal. Bits [5:1] are the ATB data signals. Bits [15:8] are the 1 hot select for which pad is selected. Reset Source: ctl_amod_g_rst_n
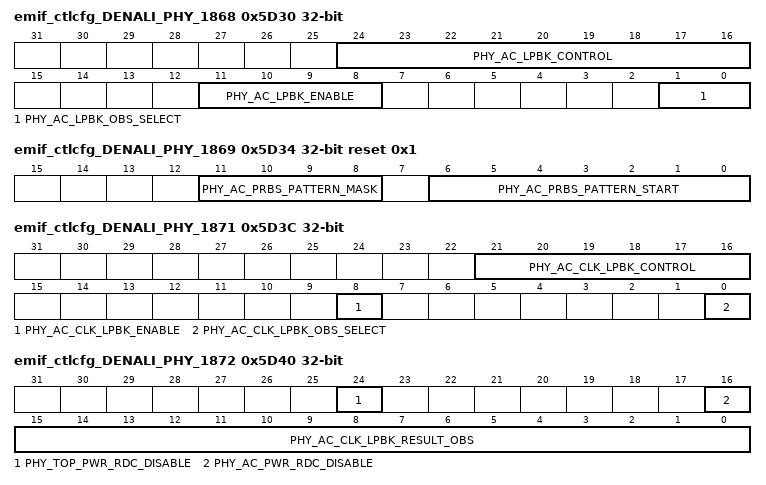
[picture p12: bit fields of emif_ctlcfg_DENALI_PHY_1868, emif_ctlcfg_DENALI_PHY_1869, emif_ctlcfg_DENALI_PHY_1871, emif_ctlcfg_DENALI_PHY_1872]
0x5D30 emif_ctlcfg_DENALI_PHY_1868
  [24:16] PHY_AC_LPBK_CONTROL — Address/control slice loopback control setting. Reset Source: ctl_amod_g_rst_n
  [11:8] PHY_AC_LPBK_ENABLE — Loopback enable for the address/control slices. Reset Source: ctl_amod_g_rst_n
  [1:0] PHY_AC_LPBK_OBS_SELECT — Select value to map an individual loopback address/control slice observation register to the global observation register. Reset Source: ctl_amod_g_rst_n
0x5D34 emif_ctlcfg_DENALI_PHY_1869 reset 0x1
  [11:8] PHY_AC_PRBS_PATTERN_MASK — PRBS7 mask signal for address/control slice. Reset Source: ctl_amod_g_rst_n
  [6:0] PHY_AC_PRBS_PATTERN_START — PRBS7 start pattern for address/control slice. Reset Source: ctl_amod_g_rst_n
0x5D38 emif_ctlcfg_DENALI_PHY_1870 ro
  [31:0] PHY_AC_LPBK_RESULT_OBS — Observation register for the loopback address/control slices. READ-ONLY Reset Source: ctl_amod_g_rst_n
0x5D3C emif_ctlcfg_DENALI_PHY_1871
  [21:16] PHY_AC_CLK_LPBK_CONTROL — Mem clk block loopback control setting. Reset Source: ctl_amod_g_rst_n
  [8] PHY_AC_CLK_LPBK_ENABLE — Loopback enable for mem clk blocks. Reset Source: ctl_amod_g_rst_n
  [0] PHY_AC_CLK_LPBK_OBS_SELECT — Select value to map an individual loopback mem clk block observation register to the global observation register. Reset Source: ctl_amod_g_rst_n
0x5D40 emif_ctlcfg_DENALI_PHY_1872 access per field
  [24] PHY_TOP_PWR_RDC_DISABLE rw — top param power reduction disable. Reset Source: ctl_amod_g_rst_n
  [16] PHY_AC_PWR_RDC_DISABLE rw — ac slice power reduction disable. Reset Source: ctl_amod_g_rst_n
  [15:0] PHY_AC_CLK_LPBK_RESULT_OBS ro — Observation register for loopback mem clk blocks. READ-ONLY Reset Source: ctl_amod_g_rst_n
0x5D44 emif_ctlcfg_DENALI_PHY_1873
  [0] PHY_AC_SLV_DLY_CTRL_GATE_DISABLE — ac slice slv_dly_control block power reduction disable. Reset Source: ctl_amod_g_rst_n
0x5D48 emif_ctlcfg_DENALI_PHY_1874
  [31:0] PHY_DATA_BYTE_ORDER_SEL — Used to define the data slice's byte swap for CA bits 7:0. Reset Source: ctl_amod_g_rst_n
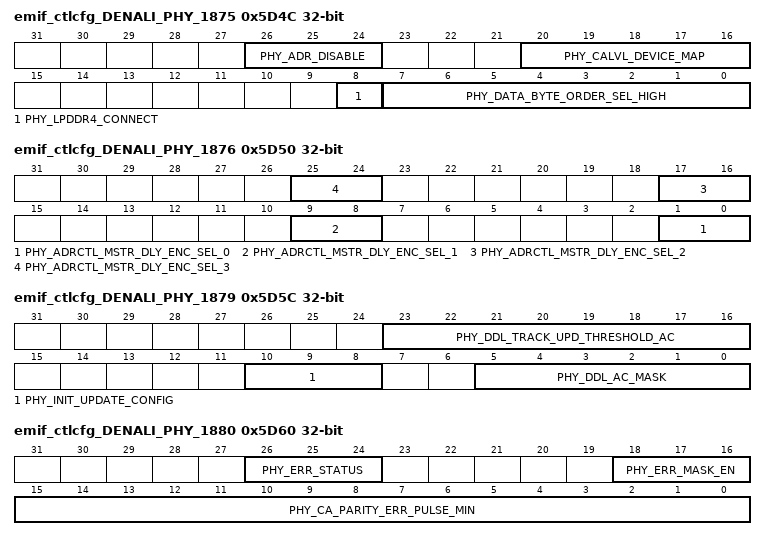
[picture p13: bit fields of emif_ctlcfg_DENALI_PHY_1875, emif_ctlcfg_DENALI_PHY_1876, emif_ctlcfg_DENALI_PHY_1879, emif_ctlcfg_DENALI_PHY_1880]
0x5D4C emif_ctlcfg_DENALI_PHY_1875
  [26:24] PHY_ADR_DISABLE — Disable the unused adr slice to save power. Reset Source: ctl_amod_g_rst_n
  [20:16] PHY_CALVL_DEVICE_MAP — Define which device's DQ feedback data bits should be used during CA training Reset Source: ctl_amod_g_rst_n
  [8] PHY_LPDDR4_CONNECT — PHY is connected to LPDDR4 devices Reset Source: ctl_amod_g_rst_n
  [7:0] PHY_DATA_BYTE_ORDER_SEL_HIGH — Used to define the data slice's byte swap for CA bits 9:8. Reset Source: ctl_amod_g_rst_n
0x5D50 emif_ctlcfg_DENALI_PHY_1876
  [8n+1:8n] PHY_ADRCTL_MSTR_DLY_ENC_SEL_{n} (n=0..3) — Select adrctl_mstr_dly_enc for the address/control slice {n} . Reset Source: ctl_amod_g_rst_n
0x5D54 emif_ctlcfg_DENALI_PHY_1877
  [31:0] PHY_DDL_AC_ENABLE — PHY Address/Control DDL BIST mode enable. Reset Source: ctl_amod_g_rst_n
0x5D58 emif_ctlcfg_DENALI_PHY_1878
  [25:0] PHY_DDL_AC_MODE — PHY Address/Control DDL BIST mode. Reset Source: ctl_amod_g_rst_n
0x5D5C emif_ctlcfg_DENALI_PHY_1879
  [23:16] PHY_DDL_TRACK_UPD_THRESHOLD_AC — Specify threshold value for PHY init update tracking for AC slice. Reset Source: ctl_amod_g_rst_n
  [10:8] PHY_INIT_UPDATE_CONFIG — PHY init update function configuration. Reset Source: ctl_amod_g_rst_n
  [5:0] PHY_DDL_AC_MASK — PHY Address/Control DDL BIST mask. Reset Source: ctl_amod_g_rst_n
0x5D60 emif_ctlcfg_DENALI_PHY_1880
  [26:24] PHY_ERR_STATUS — PHY ERROR information. Reset Source: ctl_amod_g_rst_n
  [18:16] PHY_ERR_MASK_EN — PHY ERROR information report mask enable. Reset Source: ctl_amod_g_rst_n
  [15:0] PHY_CA_PARITY_ERR_PULSE_MIN — PHY alert_n pulse width minimux value for CA parity error. Reset Source: ctl_amod_g_rst_n
{0x4000+4i} emif_ctlcfg_DENALI_PHY_{i} ro (i=1881..1884)
  [31:0] PHY_DS{i-1881}_DQS_ERR_COUNTER — PHY DATA SLICE {i-1881} DQS ERROR counter. Reset Source: ctl_amod_g_rst_n
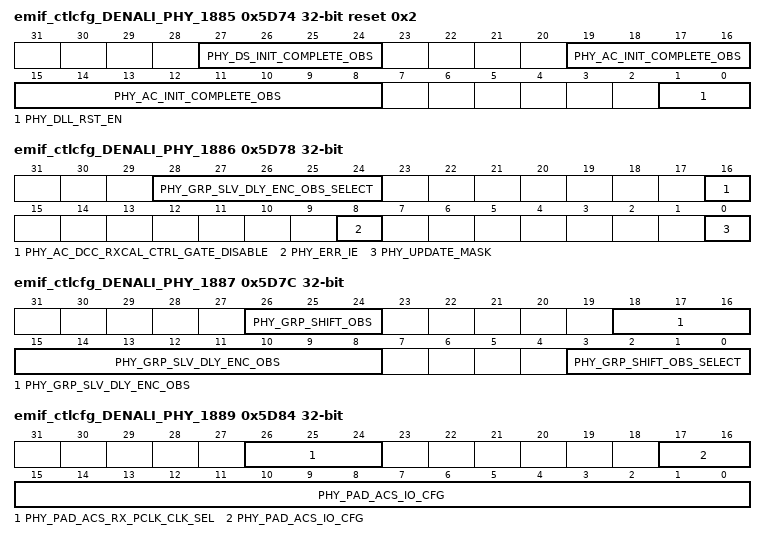
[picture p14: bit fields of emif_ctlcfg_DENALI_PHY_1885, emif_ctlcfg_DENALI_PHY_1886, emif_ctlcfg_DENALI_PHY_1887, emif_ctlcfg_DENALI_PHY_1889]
0x5D74 emif_ctlcfg_DENALI_PHY_1885 access per field reset 0x2
  [27:24] PHY_DS_INIT_COMPLETE_OBS ro — Observation register for dfi_init_complete for data slice. Bit0 is for data_slice0; bit1 is for data_slice 1,... READ-ONLY. Reset Source: ctl_amod_g_rst_n
  [19:8] PHY_AC_INIT_COMPLETE_OBS ro — Observation register for dfi_init_complete for adr and ac slice. Bit 0 is for dfi_init_complete for all slices. Bit[7:4] is for adr slice, bit4 is adr_slice0..., if the adr slice number is 3, bit7 is 0. Bit8 is for ac_slice0; bit9 is for ac_slice 1,... READ-ONLY. Reset Source: ctl_amod_g_rst_n
  [1:0] PHY_DLL_RST_EN rw — PHY DDL reset software interface enable. Reset Source: ctl_amod_g_rst_n
0x5D78 emif_ctlcfg_DENALI_PHY_1886
  [28:24] PHY_GRP_SLV_DLY_ENC_OBS_SELECT — Select value to map an individual address/control group slice target delay to the encoded value observation register. Reset Source: ctl_amod_g_rst_n
  [16] PHY_AC_DCC_RXCAL_CTRL_GATE_DISABLE — Memory clock bit slice DCC block power reduction disable. Reset Source: ctl_amod_g_rst_n
  [8] PHY_ERR_IE — Control the IE signal of IO error pad. Reset Source: ctl_amod_g_rst_n
  [0] PHY_UPDATE_MASK — Control to disable the generation of dfi_phyupd_req and use of dfi_ctrlupd_req. If this is 0 the PHY is normal mode; if this is 1, the PHY will not respond to dfi_ctrlupd_req or not to send dfi_phyupd_req Reset Source: ctl_amod_g_rst_n
0x5D7C emif_ctlcfg_DENALI_PHY_1887 access per field
  [26:24] PHY_GRP_SHIFT_OBS ro — Observation register for the address/control group automatic half cycle and cycle shift values. READ-ONLY Reset Source: ctl_amod_g_rst_n
  [18:8] PHY_GRP_SLV_DLY_ENC_OBS ro — Observation register for all address/control group slice target delay encoded values. READ-ONLY Reset Source: ctl_amod_g_rst_n
  [3:0] PHY_GRP_SHIFT_OBS_SELECT rw — Select value to map an individual address/control group slice automatic cycle/half_cycle shift settings to the observation register. Reset Source: ctl_amod_g_rst_n
0x5D80 emif_ctlcfg_DENALI_PHY_1888
  [17:0] PHY_PAD_CAL_IO_CFG_0 — Pad calibration Controls PCLK/PARK pin and vref switch. Reset Source: ctl_amod_g_rst_n
0x5D84 emif_ctlcfg_DENALI_PHY_1889
  [26:24] PHY_PAD_ACS_RX_PCLK_CLK_SEL — Controls rx_pclk clk selection for acs pad. Reset Source: ctl_amod_g_rst_n
  [17:0] PHY_PAD_ACS_IO_CFG — Controls PCLK/PARK pin for acs pad. Reset Source: ctl_amod_g_rst_n
0x5D88 emif_ctlcfg_DENALI_PHY_1890
  [0] PHY_PLL_BYPASS — PHY clock PLL bypass select. Reset Source: ctl_amod_g_rst_n
0x5D8C emif_ctlcfg_DENALI_PHY_1891
  [16] PHY_LOW_FREQ_SEL — Enables the PHY to enter/exit the PLL domain from the negative clock edge. Set to 1 at low frequencies to enable. Reset Source: ctl_amod_g_rst_n
  [12:0] PHY_PLL_CTRL — PHY clock PLL controls. Reset Source: ctl_amod_g_rst_n
0x5D90 emif_ctlcfg_DENALI_PHY_1892
  [27:24] PHY_CSLVL_DLY_STEP — Sets the delay step size plus 1 during CS training. Reset Source: ctl_amod_g_rst_n
  [19:16] PHY_CSLVL_CAPTURE_CNT — Defines the number of samples to take at each GRP target delay setting during CS training. Reset Source: ctl_amod_g_rst_n
  [11:0] PHY_PAD_VREF_CTRL_AC — Pad VREF control settings for the address/control. Reset Source: ctl_amod_g_rst_n
0x5D94 emif_ctlcfg_DENALI_PHY_1893
  [24] PHY_LVL_MEAS_DLY_STEP_ENABLE — Enables the phy_adr_meas_dly_step_value to be used instead of the phy_cslvl_dly_step parameter. Reset Source: ctl_amod_g_rst_n
  [16] PHY_SW_CSLVL_DVW_MIN_EN — Enables the software override data valid window size during CS training. Reset Source: ctl_amod_g_rst_n
  [9:0] PHY_SW_CSLVL_DVW_MIN — Sets the software override data valid window size during CS training. Reset Source: ctl_amod_g_rst_n
0x5D98 emif_ctlcfg_DENALI_PHY_1894
  [26:16] PHY_GRP1_SLAVE_DELAY_0 — Address slice target delay setting for address slice 1. Reset Source: ctl_amod_g_rst_n
  [10:0] PHY_GRP0_SLAVE_DELAY_0 — Address slice target delay setting for address slice 0. Reset Source: ctl_amod_g_rst_n
0x5D9C emif_ctlcfg_DENALI_PHY_1895
  [26:16] PHY_GRP3_SLAVE_DELAY_0 — Address slice target delay setting for address slice 3. Reset Source: ctl_amod_g_rst_n
  [10:0] PHY_GRP2_SLAVE_DELAY_0 — Address slice target delay setting for address slice 2. Reset Source: ctl_amod_g_rst_n
0x5DA0 emif_ctlcfg_DENALI_PHY_1896
  [26:16] PHY_GRP1_SLAVE_DELAY_1 — Address slice target delay setting for address slice 1. Reset Source: ctl_amod_g_rst_n
  [10:0] PHY_GRP0_SLAVE_DELAY_1 — Address slice target delay setting for address slice 0. Reset Source: ctl_amod_g_rst_n
0x5DA4 emif_ctlcfg_DENALI_PHY_1897
  [26:16] PHY_GRP3_SLAVE_DELAY_1 — Address slice target delay setting for address slice 3. Reset Source: ctl_amod_g_rst_n
  [10:0] PHY_GRP2_SLAVE_DELAY_1 — Address slice target delay setting for address slice 2. Reset Source: ctl_amod_g_rst_n
0x5DA8 emif_ctlcfg_DENALI_PHY_1898
  [26:16] PHY_GRP1_SLAVE_DELAY_2 — Address slice target delay setting for address slice 1. Reset Source: ctl_amod_g_rst_n
  [10:0] PHY_GRP0_SLAVE_DELAY_2 — Address slice target delay setting for address slice 0. Reset Source: ctl_amod_g_rst_n
0x5DAC emif_ctlcfg_DENALI_PHY_1899
  [26:16] PHY_GRP3_SLAVE_DELAY_2 — Address slice target delay setting for address slice 3. Reset Source: ctl_amod_g_rst_n
  [10:0] PHY_GRP2_SLAVE_DELAY_2 — Address slice target delay setting for address slice 2. Reset Source: ctl_amod_g_rst_n
{0x4000+4i} emif_ctlcfg_DENALI_PHY_{i} (i=1900..1903)
  [10:0] PHY_GRP{i-1900}_SLAVE_DELAY_3 — Address slice target delay setting for address slice {i-1900}. Reset Source: ctl_amod_g_rst_n
0x5DC0 emif_ctlcfg_DENALI_PHY_1904
  [2:0] PHY_CLK_DC_CAL_CLK_SEL — Determines DCC CAL clock. Reset Source: ctl_amod_g_rst_n
0x5DC4 emif_ctlcfg_DENALI_PHY_1905 reset 0xFF
  [29:0] PHY_PAD_FDBK_DRIVE — Controls drive settings for gate feedback pads. Reset Source: ctl_amod_g_rst_n
0x5DC8 emif_ctlcfg_DENALI_PHY_1906 reset 0xFF
  [17:0] PHY_PAD_FDBK_DRIVE2 — Controls drive settings [enslice/boost] for gate feedback pads. Reset Source: ctl_amod_g_rst_n
0x5DCC emif_ctlcfg_DENALI_PHY_1907
  [30:0] PHY_PAD_DATA_DRIVE — Controls drive settings for data pads. Reset Source: ctl_amod_g_rst_n
0x5DD0 emif_ctlcfg_DENALI_PHY_1908
  [31:0] PHY_PAD_DQS_DRIVE — Controls drive settings for dqs pads. Reset Source: ctl_amod_g_rst_n
0x5DD4 emif_ctlcfg_DENALI_PHY_1909 reset 0xFF
  [29:0] PHY_PAD_ADDR_DRIVE — Controls drive settings for the address/control pads. Reset Source: ctl_amod_g_rst_n
0x5DD8 emif_ctlcfg_DENALI_PHY_1910 reset 0xFFFF00
  [27:0] PHY_PAD_ADDR_DRIVE2 — Controls drive settings for the address/control pads. Reset Source: ctl_amod_g_rst_n
0x5DDC emif_ctlcfg_DENALI_PHY_1911 reset 0xFF
  [31:0] PHY_PAD_CLK_DRIVE — Controls drive settings for clock pads. Reset Source: ctl_amod_g_rst_n
0x5DE0 emif_ctlcfg_DENALI_PHY_1912 reset 0xFF
  [18:0] PHY_PAD_CLK_DRIVE2 — Controls drive settings for clock pads. Reset Source: ctl_amod_g_rst_n
0x5DE4 emif_ctlcfg_DENALI_PHY_1913 reset 0xFF
  [29:0] PHY_PAD_ERR_DRIVE — Controls drive settings for error pads. Reset Source: ctl_amod_g_rst_n
0x5DE8 emif_ctlcfg_DENALI_PHY_1914 reset 0xFFFF00
  [27:0] PHY_PAD_ERR_DRIVE2 — Controls drive settings for error pads. Reset Source: ctl_amod_g_rst_n
0x5DEC emif_ctlcfg_DENALI_PHY_1915 reset 0xFF
  [29:0] PHY_PAD_CKE_DRIVE — Controls drive settings for cke pads. Reset Source: ctl_amod_g_rst_n
0x5DF0 emif_ctlcfg_DENALI_PHY_1916 reset 0x1FFFF00
  [27:0] PHY_PAD_CKE_DRIVE2 — Controls drive settings for cke pads. Reset Source: ctl_amod_g_rst_n
0x5DF4 emif_ctlcfg_DENALI_PHY_1917 reset 0xFF
  [29:0] PHY_PAD_RST_DRIVE — Controls drive settings for reset_n pads. Reset Source: ctl_amod_g_rst_n
0x5DF8 emif_ctlcfg_DENALI_PHY_1918 reset 0x1FFFF00
  [27:0] PHY_PAD_RST_DRIVE2 — Controls drive settings for reset_n pads. Reset Source: ctl_amod_g_rst_n
0x5DFC emif_ctlcfg_DENALI_PHY_1919 reset 0xFF
  [29:0] PHY_PAD_CS_DRIVE — Controls drive settings for cs pads. Reset Source: ctl_amod_g_rst_n
0x5E00 emif_ctlcfg_DENALI_PHY_1920 reset 0x1FFFF00
  [27:0] PHY_PAD_CS_DRIVE2 — Controls drive settings for cs pads. Reset Source: ctl_amod_g_rst_n
0x5E04 emif_ctlcfg_DENALI_PHY_1921 reset 0xFF
  [29:0] PHY_PAD_ODT_DRIVE — Controls drive settings for odt pads. Reset Source: ctl_amod_g_rst_n
0x5E08 emif_ctlcfg_DENALI_PHY_1922 reset 0x1FFFF00
  [27:0] PHY_PAD_ODT_DRIVE2 — Controls drive settings for odt pads. Reset Source: ctl_amod_g_rst_n
0x5E0C emif_ctlcfg_DENALI_PHY_1923
  [30:24] PHY_CAL_SETTLING_PRD_0 — Number of clock cycles to extend dfi_phyupd_req after the ack is received for settling of final values Reset Source: ctl_amod_g_rst_n
  [23:8] PHY_CAL_VREF_SWITCH_TIMER_0 — The settling time for a switch in VREF during IO pad calibration. Reset Source: ctl_amod_g_rst_n
  [2:0] PHY_CAL_CLK_SELECT_0 — Pad calibration pad clock frequency select setting for block 0. Reset Source: ctl_amod_g_rst_n
